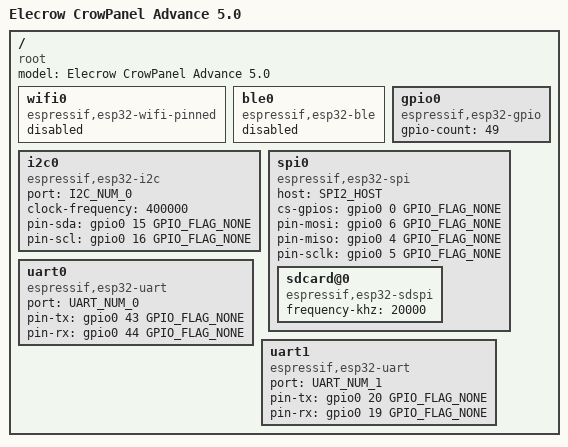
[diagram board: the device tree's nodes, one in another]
/dts-v1/;

#include <tactility/bindings/root.h>
#include <tactility/bindings/esp32_ble.h>
#include <tactility/bindings/esp32_wifi_pinned.h>
#include <tactility/bindings/esp32_gpio.h>
#include <tactility/bindings/esp32_i2c.h>
#include <tactility/bindings/esp32_spi.h>
#include <tactility/bindings/esp32_uart.h>
#include <tactility/bindings/esp32_sdspi.h>

/ {
	compatible = "root";
	model = "Elecrow CrowPanel Advance 5.0";

	wifi0 {
		compatible = "espressif,esp32-wifi-pinned";
		status = "disabled";
	};

	ble0 {
		compatible = "espressif,esp32-ble";
		status = "disabled";
	};

	gpio0 {
		compatible = "espressif,esp32-gpio";
		gpio-count = <49>;
	};

	i2c0 {
		compatible = "espressif,esp32-i2c";
		port = <I2C_NUM_0>;
		clock-frequency = <400000>;
		pin-sda = <&gpio0 15 GPIO_FLAG_NONE>;
		pin-scl = <&gpio0 16 GPIO_FLAG_NONE>;
	};

	spi0 {
		compatible = "espressif,esp32-spi";
		host = <SPI2_HOST>;
		cs-gpios = <&gpio0 0 GPIO_FLAG_NONE>;
		pin-mosi = <&gpio0 6 GPIO_FLAG_NONE>;
		pin-miso = <&gpio0 4 GPIO_FLAG_NONE>;
		pin-sclk = <&gpio0 5 GPIO_FLAG_NONE>;
	
		sdcard@0 {
			compatible = "espressif,esp32-sdspi";
			frequency-khz = <20000>;
		};
	};

	uart0 {
		compatible = "espressif,esp32-uart";
		port = <UART_NUM_0>;
		pin-tx = <&gpio0 43 GPIO_FLAG_NONE>;
		pin-rx = <&gpio0 44 GPIO_FLAG_NONE>;
	};

	uart1 {
		compatible = "espressif,esp32-uart";
		port = <UART_NUM_1>;
		pin-tx = <&gpio0 20 GPIO_FLAG_NONE>;
		pin-rx = <&gpio0 19 GPIO_FLAG_NONE>;
	};
};
